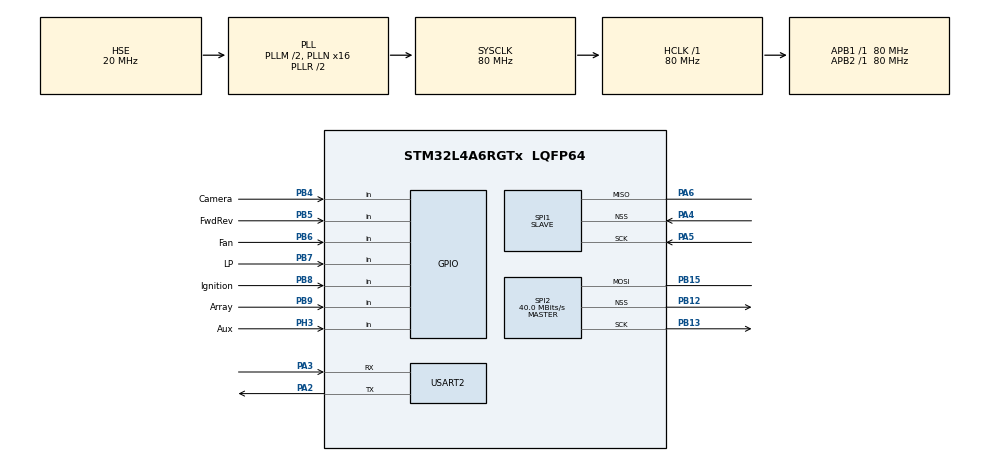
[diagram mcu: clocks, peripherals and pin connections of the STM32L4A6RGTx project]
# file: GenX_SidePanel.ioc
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FREERTOS.Tasks01=defaultTask,0,128,StartDefaultTask,Default,NULL
Mcu.Family=STM32L4
Mcu.Name=STM32L4A6RGTx
Mcu.Package=LQFP64
NVIC.PriorityGroup=NVIC_PRIORITYGROUP_4
PA13\ (JTMS/SWDIO).Mode=Serial_Wire
PA13\ (JTMS/SWDIO).Signal=SYS_JTMS-SWDIO
PA14\ (JTCK/SWCLK).Mode=Serial_Wire
PA14\ (JTCK/SWCLK).Signal=SYS_JTCK-SWCLK
PA2.Mode=Asynchronous
PA2.Signal=USART2_TX
PA3.Mode=Asynchronous
PA3.Signal=USART2_RX
PA4.Mode=NSS_Signal_Hard_Input
PA4.Signal=SPI1_NSS
PA5.Mode=Simplex_Bidirectional_Slave
PA5.Signal=SPI1_SCK
PA6.Mode=Simplex_Bidirectional_Slave
PA6.Signal=SPI1_MISO
PB12.Mode=NSS_Signal_Hard_Output
PB12.Signal=SPI2_NSS
PB13.Mode=Simplex_Bidirectional_Master
PB13.Signal=SPI2_SCK
PB15.Mode=Simplex_Bidirectional_Master
PB15.Signal=SPI2_MOSI
PB4\ (NJTRST).GPIO_Label=Camera
PB4\ (NJTRST).Signal=GPIO_Input
PB5.GPIO_Label=FwdRev
PB5.Signal=GPIO_Input
PB6.GPIO_Label=Fan
PB6.Signal=GPIO_Input
PB7.GPIO_Label=LP
PB7.Signal=GPIO_Input
PB8.GPIO_Label=Ignition
PB8.Signal=GPIO_Input
PB9.GPIO_Label=Array
PB9.Signal=GPIO_Input
PH0-OSC_IN\ (PH0).Mode=HSE-External-Oscillator
PH0-OSC_IN\ (PH0).Signal=RCC_OSC_IN
PH1-OSC_OUT\ (PH1).Mode=HSE-External-Oscillator
PH1-OSC_OUT\ (PH1).Signal=RCC_OSC_OUT
PH3-BOOT0.GPIO_Label=Aux
PH3-BOOT0.Signal=GPIO_Input
ProjectManager.HeapSize=0x200
ProjectManager.StackSize=0x400
ProjectManager.TargetToolchain=TrueSTUDIO
RCC.ADCFreq_Value=40000000
RCC.AHBFreq_Value=80000000
RCC.APB1Freq_Value=80000000
RCC.APB1TimFreq_Value=80000000
RCC.APB2Freq_Value=80000000
RCC.APB2TimFreq_Value=80000000
RCC.CortexFreq_Value=80000000
RCC.HCLKFreq_Value=80000000
RCC.HSE_VALUE=20000000
RCC.HSI48_VALUE=48000000
RCC.HSI_VALUE=16000000
RCC.LSE_VALUE=32768
RCC.MSI_VALUE=4000000
RCC.PLLM=2
RCC.PLLN=16
RCC.PLLSourceVirtual=RCC_PLLSOURCE_HSE
RCC.SYSCLKFreq_VALUE=80000000
RCC.SYSCLKSource=RCC_SYSCLKSOURCE_PLLCLK
RCC.USBFreq_Value=40000000
RCC.VCOOutputFreq_Value=160000000
SPI1.Direction=SPI_DIRECTION_1LINE
SPI1.Mode=SPI_MODE_SLAVE
SPI1.VirtualNSS=VM_NSSHARD
SPI1.VirtualType=VM_SLAVE
SPI2.BaudRatePrescaler=SPI_BAUDRATEPRESCALER_2
SPI2.CalculateBaudRate=40.0 MBits/s
SPI2.Direction=SPI_DIRECTION_1LINE
SPI2.Mode=SPI_MODE_MASTER
SPI2.VirtualNSS=VM_NSSHARD
SPI2.VirtualType=VM_MASTER
USART2.VirtualMode-Asynchronous=VM_ASYNC
VP_CRC_VS_CRC.Mode=CRC_Activate
VP_FREERTOS_VS_CMSIS_V1.Mode=CMSIS_V1
board=custom

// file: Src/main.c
/* USER CODE BEGIN Header */
/**
  ******************************************************************************
  * @file           : main.c
  * @brief          : Main program body
  ******************************************************************************
  * @attention
  *
  * <h2><center>&copy; Copyright (c) 2019 STMicroelectronics.
  * All rights reserved.</center></h2>
  *
  * This software component is licensed by ST under Ultimate Liberty license
  * SLA0044, the "License"; You may not use this file except in compliance with
  * the License. You may obtain a copy of the License at:
  *                             www.st.com/SLA0044
  *
  ******************************************************************************
  */
/* USER CODE END Header */

#include "main.h"
#include "cmsis_os.h"
#include "crc.h"
#include "spi.h"
#include "usart.h"
#include "gpio.h"

void SystemClock_Config(void);
void MX_FREERTOS_Init(void);

int main(void)
{

  /* MCU Configuration--------------------------------------------------------*/

  /* Reset of all peripherals, Initializes the Flash interface and the Systick. */
  HAL_Init();

  /* Configure the system clock */
  SystemClock_Config();

  /* Initialize all configured peripherals */
  MX_GPIO_Init();
  MX_SPI1_Init();
  MX_SPI2_Init();
  MX_USART2_UART_Init();
  MX_CRC_Init();

  /* Call init function for freertos objects (in freertos.c) */
  MX_FREERTOS_Init();

  /* Start scheduler */
  osKernelStart();

  /* We should never get here as control is now taken by the scheduler */

  /* Infinite loop */
  while (1)
  {

  }
}

void SystemClock_Config(void)
{
  RCC_OscInitTypeDef RCC_OscInitStruct = {0};
  RCC_ClkInitTypeDef RCC_ClkInitStruct = {0};
  RCC_PeriphCLKInitTypeDef PeriphClkInit = {0};

  /** Initializes the CPU, AHB and APB busses clocks
  */
  RCC_OscInitStruct.OscillatorType = RCC_OSCILLATORTYPE_HSE;
  RCC_OscInitStruct.HSEState = RCC_HSE_ON;
  RCC_OscInitStruct.PLL.PLLState = RCC_PLL_ON;
  RCC_OscInitStruct.PLL.PLLSource = RCC_PLLSOURCE_HSE;
  RCC_OscInitStruct.PLL.PLLM = 2;
  RCC_OscInitStruct.PLL.PLLN = 16;
  RCC_OscInitStruct.PLL.PLLP = RCC_PLLP_DIV2;
  RCC_OscInitStruct.PLL.PLLQ = RCC_PLLQ_DIV2;
  RCC_OscInitStruct.PLL.PLLR = RCC_PLLR_DIV2;
  if (HAL_RCC_OscConfig(&RCC_OscInitStruct) != HAL_OK)
  {
    Error_Handler();
  }
  /** Initializes the CPU, AHB and APB busses clocks
  */
  RCC_ClkInitStruct.ClockType = RCC_CLOCKTYPE_HCLK|RCC_CLOCKTYPE_SYSCLK
                              |RCC_CLOCKTYPE_PCLK1|RCC_CLOCKTYPE_PCLK2;
  RCC_ClkInitStruct.SYSCLKSource = RCC_SYSCLKSOURCE_PLLCLK;
  RCC_ClkInitStruct.AHBCLKDivider = RCC_SYSCLK_DIV1;
  RCC_ClkInitStruct.APB1CLKDivider = RCC_HCLK_DIV1;
  RCC_ClkInitStruct.APB2CLKDivider = RCC_HCLK_DIV1;

  if (HAL_RCC_ClockConfig(&RCC_ClkInitStruct, FLASH_LATENCY_4) != HAL_OK)
  {
    Error_Handler();
  }
  PeriphClkInit.PeriphClockSelection = RCC_PERIPHCLK_USART2;
  PeriphClkInit.Usart2ClockSelection = RCC_USART2CLKSOURCE_PCLK1;
  if (HAL_RCCEx_PeriphCLKConfig(&PeriphClkInit) != HAL_OK)
  {
    Error_Handler();
  }
  /** Configure the main internal regulator output voltage
  */
  if (HAL_PWREx_ControlVoltageScaling(PWR_REGULATOR_VOLTAGE_SCALE1) != HAL_OK)
  {
    Error_Handler();
  }
}

void Error_Handler(void)
{
}

/************************ (C) COPYRIGHT STMicroelectronics *****END OF FILE****/

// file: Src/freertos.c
/* USER CODE BEGIN Header */
/**
  ******************************************************************************
  * File Name          : freertos.c
  * Description        : Code for freertos applications
  ******************************************************************************
  * @attention
  *
  * <h2><center>&copy; Copyright (c) 2019 STMicroelectronics.
  * All rights reserved.</center></h2>
  *
  * This software component is licensed by ST under Ultimate Liberty license
  * SLA0044, the "License"; You may not use this file except in compliance with
  * the License. You may obtain a copy of the License at:
  *                             www.st.com/SLA0044
  *
  ******************************************************************************
  */
/* USER CODE END Header */

#include "FreeRTOS.h"
#include "task.h"
#include "main.h"
#include "cmsis_os.h"

/* USER CODE BEGIN Includes */
#include "switchStates.h"
#include "serializer.h"

/* USER CODE END Includes */

/* USER CODE BEGIN PD */
#define switchStatePeriod   50  //ms

/* USER CODE END PD */

/* USER CODE BEGIN Variables */
osThreadId switchStateTaskHandle;

/* USER CODE END Variables */
osThreadId defaultTaskHandle;

/* USER CODE BEGIN FunctionPrototypes */
void getSwitchState(void const * argument);

/* USER CODE END FunctionPrototypes */

void MX_FREERTOS_Init(void); /* (MISRA C 2004 rule 8.1) */

void MX_FREERTOS_Init(void) {

  /* Create the thread(s) */
  /* definition and creation of the switchStateTask */
  osThreadDef(switchStateTask, getSwitchState, osPriorityNormal, 0, 128);
  switchStateTaskHandle = osThreadCreate(osThread(switchStateTask), NULL);

}

/* USER CODE BEGIN Application */
void getSwitchState(void const * argument)
{

  /* Infinite loop */
  uint32_t lastTickTime;
  char buf[MSG_LEN_SS];
  uint8_t switchStates = 0x0;
  lastTickTime = xTaskGetTickCount();
  for(;;)
  	  {
	  	  // TODO: Place holders
	  	  switchStates = getSwitchStates();
	      serializeSwitchStates(&buf, switchStates);    // Assemble Message
	  	  send_data(&buf, MSG_LEN_SS);				// Send message to UART
	  	  osDelayUntil(&lastTickTime, switchStatePeriod);
  	  }

}
/* USER CODE END Application */

/************************ (C) COPYRIGHT STMicroelectronics *****END OF FILE****/
